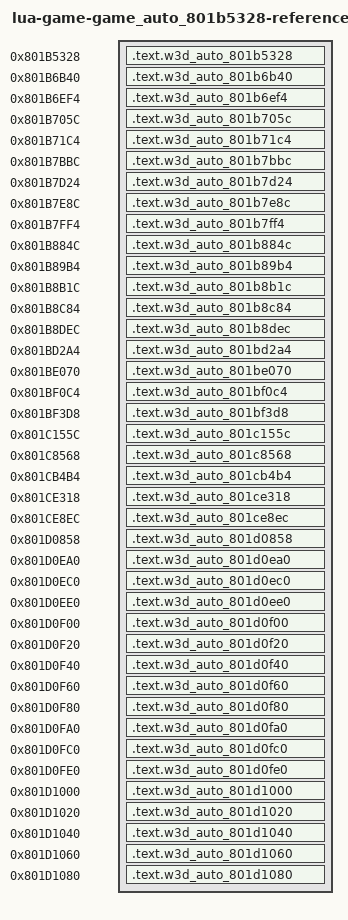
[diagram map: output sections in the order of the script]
/* Generated reference-only placements. All bodies are source-built. */
OUTPUT_FORMAT("elf32-powerpc")
OUTPUT_ARCH(powerpc)
ENTRY(w3d_auto_801b5328)
_SDA_BASE_ = 0x804b2540;
_SDA2_BASE_ = 0x804c2540;
fn_801E8D9C = 0x801e8d9c;
SECTIONS {
  .text.w3d_auto_801b5328 0x801b5328 : { *(.text.w3d_auto_801b5328) }
  .text.w3d_auto_801b6b40 0x801b6b40 : { *(.text.w3d_auto_801b6b40) }
  .text.w3d_auto_801b6ef4 0x801b6ef4 : { *(.text.w3d_auto_801b6ef4) }
  .text.w3d_auto_801b705c 0x801b705c : { *(.text.w3d_auto_801b705c) }
  .text.w3d_auto_801b71c4 0x801b71c4 : { *(.text.w3d_auto_801b71c4) }
  .text.w3d_auto_801b7bbc 0x801b7bbc : { *(.text.w3d_auto_801b7bbc) }
  .text.w3d_auto_801b7d24 0x801b7d24 : { *(.text.w3d_auto_801b7d24) }
  .text.w3d_auto_801b7e8c 0x801b7e8c : { *(.text.w3d_auto_801b7e8c) }
  .text.w3d_auto_801b7ff4 0x801b7ff4 : { *(.text.w3d_auto_801b7ff4) }
  .text.w3d_auto_801b884c 0x801b884c : { *(.text.w3d_auto_801b884c) }
  .text.w3d_auto_801b89b4 0x801b89b4 : { *(.text.w3d_auto_801b89b4) }
  .text.w3d_auto_801b8b1c 0x801b8b1c : { *(.text.w3d_auto_801b8b1c) }
  .text.w3d_auto_801b8c84 0x801b8c84 : { *(.text.w3d_auto_801b8c84) }
  .text.w3d_auto_801b8dec 0x801b8dec : { *(.text.w3d_auto_801b8dec) }
  .text.w3d_auto_801bd2a4 0x801bd2a4 : { *(.text.w3d_auto_801bd2a4) }
  .text.w3d_auto_801be070 0x801be070 : { *(.text.w3d_auto_801be070) }
  .text.w3d_auto_801bf0c4 0x801bf0c4 : { *(.text.w3d_auto_801bf0c4) }
  .text.w3d_auto_801bf3d8 0x801bf3d8 : { *(.text.w3d_auto_801bf3d8) }
  .text.w3d_auto_801c155c 0x801c155c : { *(.text.w3d_auto_801c155c) }
  .text.w3d_auto_801c8568 0x801c8568 : { *(.text.w3d_auto_801c8568) }
  .text.w3d_auto_801cb4b4 0x801cb4b4 : { *(.text.w3d_auto_801cb4b4) }
  .text.w3d_auto_801ce318 0x801ce318 : { *(.text.w3d_auto_801ce318) }
  .text.w3d_auto_801ce8ec 0x801ce8ec : { *(.text.w3d_auto_801ce8ec) }
  .text.w3d_auto_801d0858 0x801d0858 : { *(.text.w3d_auto_801d0858) }
  .text.w3d_auto_801d0ea0 0x801d0ea0 : { *(.text.w3d_auto_801d0ea0) }
  .text.w3d_auto_801d0ec0 0x801d0ec0 : { *(.text.w3d_auto_801d0ec0) }
  .text.w3d_auto_801d0ee0 0x801d0ee0 : { *(.text.w3d_auto_801d0ee0) }
  .text.w3d_auto_801d0f00 0x801d0f00 : { *(.text.w3d_auto_801d0f00) }
  .text.w3d_auto_801d0f20 0x801d0f20 : { *(.text.w3d_auto_801d0f20) }
  .text.w3d_auto_801d0f40 0x801d0f40 : { *(.text.w3d_auto_801d0f40) }
  .text.w3d_auto_801d0f60 0x801d0f60 : { *(.text.w3d_auto_801d0f60) }
  .text.w3d_auto_801d0f80 0x801d0f80 : { *(.text.w3d_auto_801d0f80) }
  .text.w3d_auto_801d0fa0 0x801d0fa0 : { *(.text.w3d_auto_801d0fa0) }
  .text.w3d_auto_801d0fc0 0x801d0fc0 : { *(.text.w3d_auto_801d0fc0) }
  .text.w3d_auto_801d0fe0 0x801d0fe0 : { *(.text.w3d_auto_801d0fe0) }
  .text.w3d_auto_801d1000 0x801d1000 : { *(.text.w3d_auto_801d1000) }
  .text.w3d_auto_801d1020 0x801d1020 : { *(.text.w3d_auto_801d1020) }
  .text.w3d_auto_801d1040 0x801d1040 : { *(.text.w3d_auto_801d1040) }
  .text.w3d_auto_801d1060 0x801d1060 : { *(.text.w3d_auto_801d1060) }
  .text.w3d_auto_801d1080 0x801d1080 : { *(.text.w3d_auto_801d1080) }
  /DISCARD/ : { *(.text*) *(.rodata*) *(.data*) *(.bss*) *(.sdata*) *(.sbss*) *(.comment) }
}
